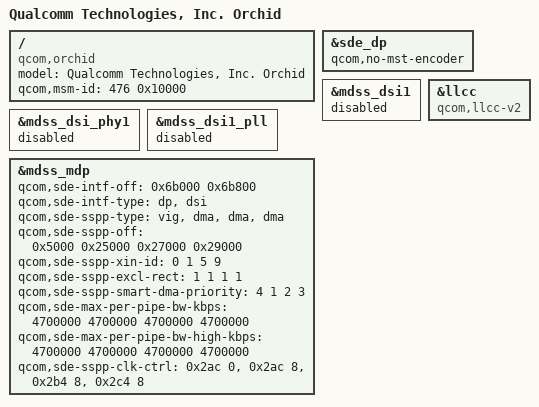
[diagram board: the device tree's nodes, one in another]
#include "lito-v2.dtsi"
#include "pmk8350.dtsi"
#include "magnus.dtsi"

/ {
	model = "Qualcomm Technologies, Inc. Orchid";
	compatible = "qcom,orchid";
	qcom,msm-id = <476 0x10000>;
};

&sde_dp {
	/delete-property/ qcom,mst-enable;
	qcom,no-mst-encoder;
};

&mdss_dsi1 {
	status = "disabled";
};

&mdss_dsi_phy1 {
	status = "disabled";
};

&mdss_dsi1_pll {
	status = "disabled";
};

&mdss_mdp {
	qcom,sde-intf-off = <0x6b000 0x6b800>;
	qcom,sde-intf-type = "dp", "dsi";
	qcom,sde-sspp-type = "vig", "dma", "dma", "dma";
	qcom,sde-sspp-off = <0x5000 0x25000 0x27000 0x29000>;
	qcom,sde-sspp-xin-id = <0 1 5 9>;
	qcom,sde-sspp-excl-rect = <1 1 1 1>;
	qcom,sde-sspp-smart-dma-priority = <4 1 2 3>;
	qcom,sde-max-per-pipe-bw-kbps = <4700000 4700000 4700000
					4700000>;
	qcom,sde-max-per-pipe-bw-high-kbps = <4700000 4700000 4700000
					4700000>;
	qcom,sde-sspp-clk-ctrl = <0x2ac 0>, <0x2ac 8>, <0x2b4 8>,
					 <0x2c4 8>;
};

&llcc {
	compatible = "qcom,llcc-v2";
};
